# HDSC_HC32F480 register map
Vendor: HDSC Co.Ltd; Series: ARMCM4; File version: 1.2
CPU: CM0 r0p0, little endian, no MPU, no FPU, 3 interrupt priority bits
Registers are 16-bit, read-write, reset 0x0 unless marked. A register's access mark holds for its fields unless they carry their own. Offsets are from the block's base; [hi:lo] are bit positions; {n}, {i} and the like mark numbered series; 'fields as' and 'values as' point back to an identical list.

## USF
Base 0x400C0000
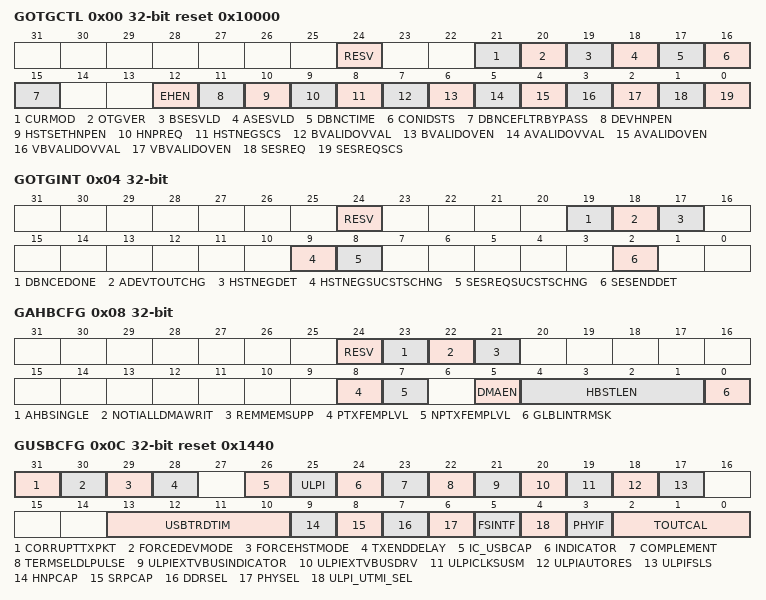
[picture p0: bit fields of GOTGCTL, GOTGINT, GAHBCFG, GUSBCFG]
0x00 GOTGCTL 32-bit ro reset 0x10000
  [24] RESV rw, [21] CURMOD, [20] OTGVER rw, [19] BSESVLD, [18] ASESVLD, [17] DBNCTIME, [16] CONIDSTS, [15] DBNCEFLTRBYPASS rw, [12] EHEN rw, [11] DEVHNPEN rw, [10] HSTSETHNPEN rw, [9] HNPREQ rw, [8] HSTNEGSCS, [7] BVALIDOVVAL rw, [6] BVALIDOVEN rw, [5] AVALIDOVVAL rw, [4] AVALIDOVEN rw, [3] VBVALIDOVVAL rw, [2] VBVALIDOVEN rw, [1] SESREQ rw, [0] SESREQSCS
0x04 GOTGINT 32-bit
  [24] RESV, [19] DBNCEDONE, [18] ADEVTOUTCHG, [17] HSTNEGDET, [9] HSTNEGSUCSTSCHNG, [8] SESREQSUCSTSCHNG, [2] SESENDDET
0x08 GAHBCFG 32-bit
  [24] RESV, [23] AHBSINGLE, [22] NOTIALLDMAWRIT, [21] REMMEMSUPP, [8] PTXFEMPLVL, [7] NPTXFEMPLVL, [5] DMAEN, [4:1] HBSTLEN, [0] GLBLINTRMSK
0x0C GUSBCFG 32-bit reset 0x1440
  [31] CORRUPTTXPKT wo, [30] FORCEDEVMODE, [29] FORCEHSTMODE, [28] TXENDDELAY, [26] IC_USBCAP, [25] ULPI, [24] INDICATOR, [23] COMPLEMENT, [22] TERMSELDLPULSE, [21] ULPIEXTVBUSINDICATOR, [20] ULPIEXTVBUSDRV, [19] ULPICLKSUSM, [18] ULPIAUTORES, [17] ULPIFSLS, [13:10] USBTRDTIM, [9] HNPCAP, [8] SRPCAP, [7] DDRSEL, [6] PHYSEL, [5] FSINTF, [4] ULPI_UTMI_SEL, [3] PHYIF, [2:0] TOUTCAL
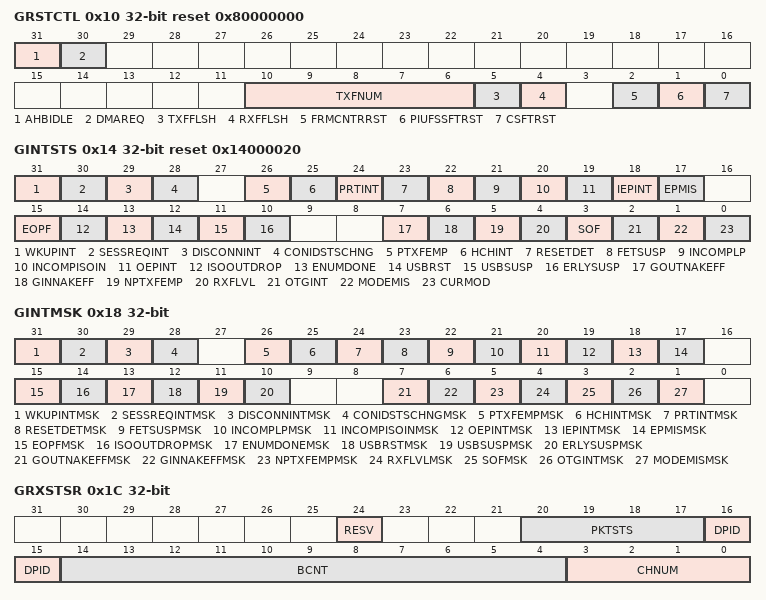
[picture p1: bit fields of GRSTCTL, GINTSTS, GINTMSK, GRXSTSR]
0x10 GRSTCTL 32-bit reset 0x80000000
  [31] AHBIDLE ro, [30] DMAREQ ro, [10:6] TXFNUM, [5] TXFFLSH, [4] RXFFLSH, [2] FRMCNTRRST, [1] PIUFSSFTRST, [0] CSFTRST
0x14 GINTSTS 32-bit ro reset 0x14000020
  [31] WKUPINT rw, [30] SESSREQINT rw, [29] DISCONNINT rw, [28] CONIDSTSCHNG rw, [26] PTXFEMP, [25] HCHINT, [24] PRTINT, [23] RESETDET rw, [22] FETSUSP rw, [21] INCOMPLP rw, [20] INCOMPISOIN rw, [19] OEPINT, [18] IEPINT, [17] EPMIS rw, [15] EOPF rw, [14] ISOOUTDROP rw, [13] ENUMDONE rw, [12] USBRST rw, [11] USBSUSP rw, [10] ERLYSUSP rw, [7] GOUTNAKEFF, [6] GINNAKEFF, [5] NPTXFEMP, [4] RXFLVL, [3] SOF rw, [2] OTGINT, [1] MODEMIS rw, [0] CURMOD
0x18 GINTMSK 32-bit
  [31] WKUPINTMSK, [30] SESSREQINTMSK, [29] DISCONNINTMSK, [28] CONIDSTSCHNGMSK, [26] PTXFEMPMSK, [25] HCHINTMSK, [24] PRTINTMSK, [23] RESETDETMSK, [22] FETSUSPMSK, [21] INCOMPLPMSK, [20] INCOMPISOINMSK, [19] OEPINTMSK, [18] IEPINTMSK, [17] EPMISMSK, [15] EOPFMSK, [14] ISOOUTDROPMSK, [13] ENUMDONEMSK, [12] USBRSTMSK, [11] USBSUSPMSK, [10] ERLYSUSPMSK, [7] GOUTNAKEFFMSK, [6] GINNAKEFFMSK, [5] NPTXFEMPMSK, [4] RXFLVLMSK, [3] SOFMSK, [2] OTGINTMSK, [1] MODEMISMSK
0x1C GRXSTSR 32-bit ro
  [24] RESV rw, [20:17] PKTSTS, [16:15] DPID, [14:4] BCNT, [3:0] CHNUM
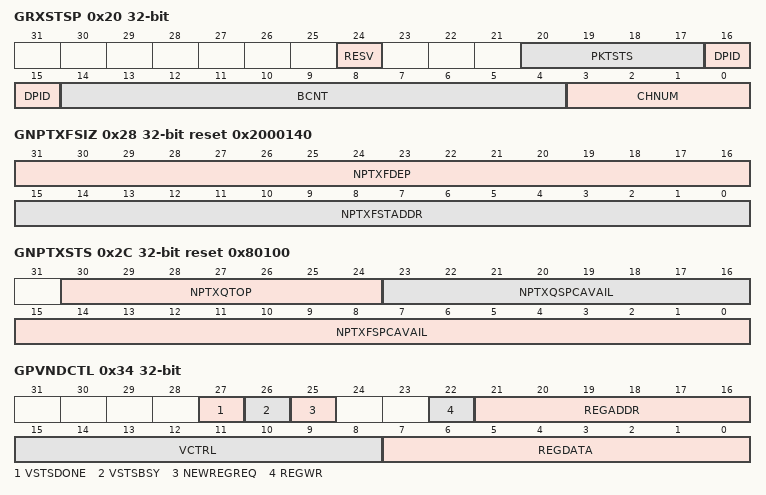
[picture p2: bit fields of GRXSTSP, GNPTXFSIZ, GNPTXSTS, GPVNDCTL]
0x20 GRXSTSP 32-bit ro
  [24] RESV rw, [20:17] PKTSTS, [16:15] DPID, [14:4] BCNT, [3:0] CHNUM
0x24 GRXFSIZ reset 0x140
  [10:0] RXFDEP
0x28 GNPTXFSIZ 32-bit reset 0x2000140
  [31:16] NPTXFDEP, [15:0] NPTXFSTADDR
0x2C GNPTXSTS 32-bit ro reset 0x80100
  [30:24] NPTXQTOP, [23:16] NPTXQSPCAVAIL, [15:0] NPTXFSPCAVAIL
0x34 GPVNDCTL 32-bit
  [27] VSTSDONE, [26] VSTSBSY ro, [25] NEWREGREQ, [22] REGWR, [21:16] REGADDR, [15:8] VCTRL, [7:0] REGDATA
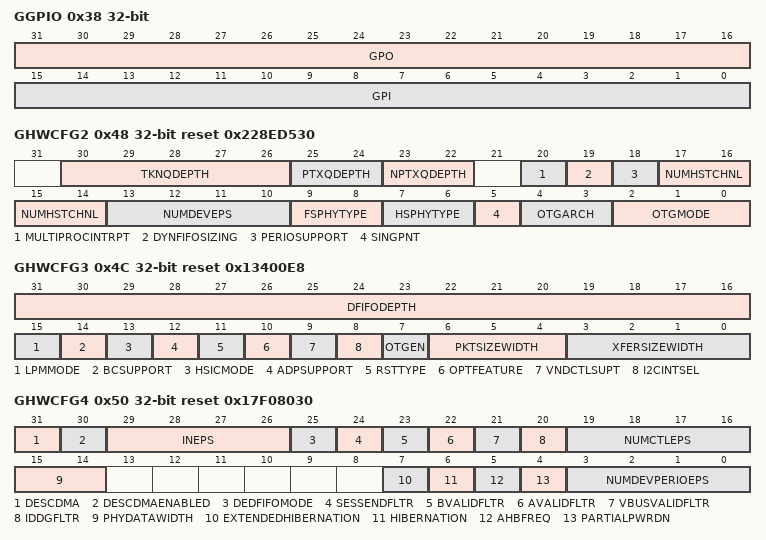
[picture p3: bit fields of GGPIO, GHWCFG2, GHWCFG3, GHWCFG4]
0x38 GGPIO 32-bit ro
  [31:16] GPO rw, [15:0] GPI
0x3C GUID 32-bit ro reset 0x12345678
0x40 GSNPSID 32-bit ro reset 0x4F54330A
0x44 GHWCFG1 32-bit ro
0x48 GHWCFG2 32-bit ro reset 0x228ED530
  [30:26] TKNQDEPTH, [25:24] PTXQDEPTH, [23:22] NPTXQDEPTH, [20] MULTIPROCINTRPT, [19] DYNFIFOSIZING, [18] PERIOSUPPORT, [17:14] NUMHSTCHNL, [13:10] NUMDEVEPS, [9:8] FSPHYTYPE, [7:6] HSPHYTYPE, [5] SINGPNT, [4:3] OTGARCH, [2:0] OTGMODE
0x4C GHWCFG3 32-bit ro reset 0x13400E8
  [31:16] DFIFODEPTH, [15] LPMMODE, [14] BCSUPPORT, [13] HSICMODE, [12] ADPSUPPORT, [11] RSTTYPE, [10] OPTFEATURE, [9] VNDCTLSUPT, [8] I2CINTSEL, [7] OTGEN, [6:4] PKTSIZEWIDTH, [3:0] XFERSIZEWIDTH
0x50 GHWCFG4 32-bit ro reset 0x17F08030
  [31] DESCDMA, [30] DESCDMAENABLED, [29:26] INEPS, [25] DEDFIFOMODE, [24] SESSENDFLTR, [23] BVALIDFLTR, [22] AVALIDFLTR, [21] VBUSVALIDFLTR, [20] IDDGFLTR, [19:16] NUMCTLEPS, [15:14] PHYDATAWIDTH, [7] EXTENDEDHIBERNATION, [6] HIBERNATION, [5] AHBFREQ, [4] PARTIALPWRDN, [3:0] NUMDEVPERIOEPS
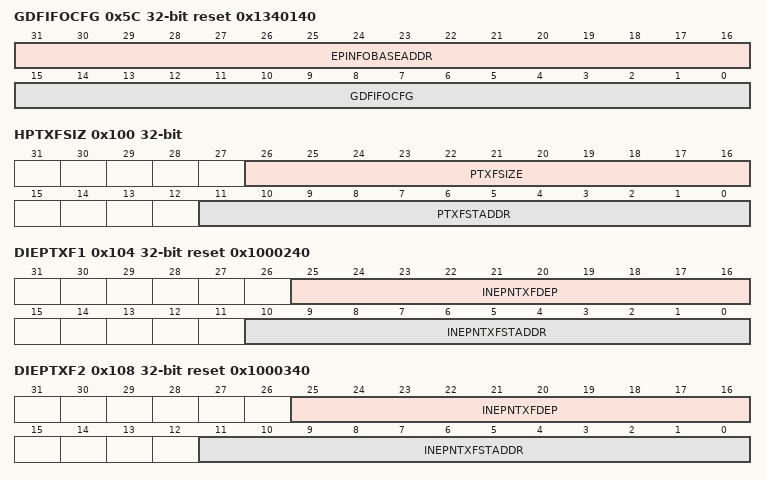
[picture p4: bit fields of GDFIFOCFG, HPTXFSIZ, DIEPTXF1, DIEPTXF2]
0x5C GDFIFOCFG 32-bit reset 0x1340140
  [31:16] EPINFOBASEADDR, [15:0] GDFIFOCFG
0x100 HPTXFSIZ 32-bit
  [26:16] PTXFSIZE, [11:0] PTXFSTADDR
0x104 DIEPTXF1 32-bit reset 0x1000240
  [25:16] INEPNTXFDEP, [10:0] INEPNTXFSTADDR
0x108 DIEPTXF2 32-bit reset 0x1000340
  [25:16] INEPNTXFDEP, [11:0] INEPNTXFSTADDR
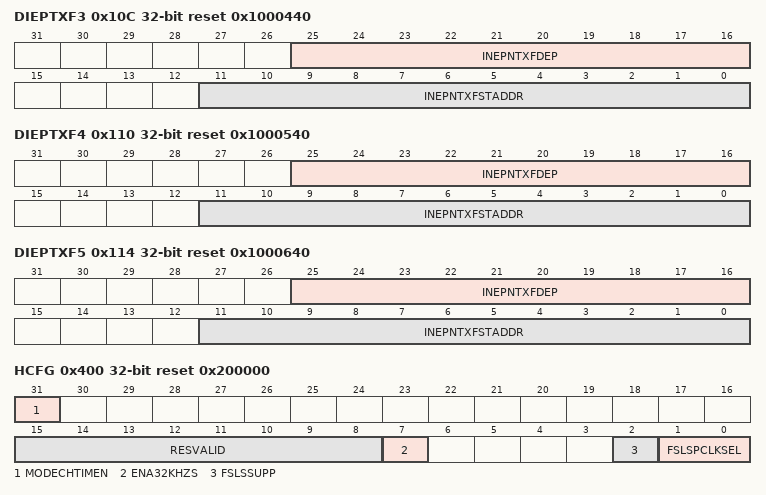
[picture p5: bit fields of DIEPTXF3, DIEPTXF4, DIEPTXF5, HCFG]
0x10C DIEPTXF3 32-bit reset 0x1000440
  [25:16] INEPNTXFDEP, [11:0] INEPNTXFSTADDR
0x110 DIEPTXF4 32-bit reset 0x1000540
  [25:16] INEPNTXFDEP, [11:0] INEPNTXFSTADDR
0x114 DIEPTXF5 32-bit reset 0x1000640
  [25:16] INEPNTXFDEP, [11:0] INEPNTXFSTADDR
0x400 HCFG 32-bit reset 0x200000
  [31] MODECHTIMEN, [15:8] RESVALID, [7] ENA32KHZS, [2] FSLSSUPP, [1:0] FSLSPCLKSEL
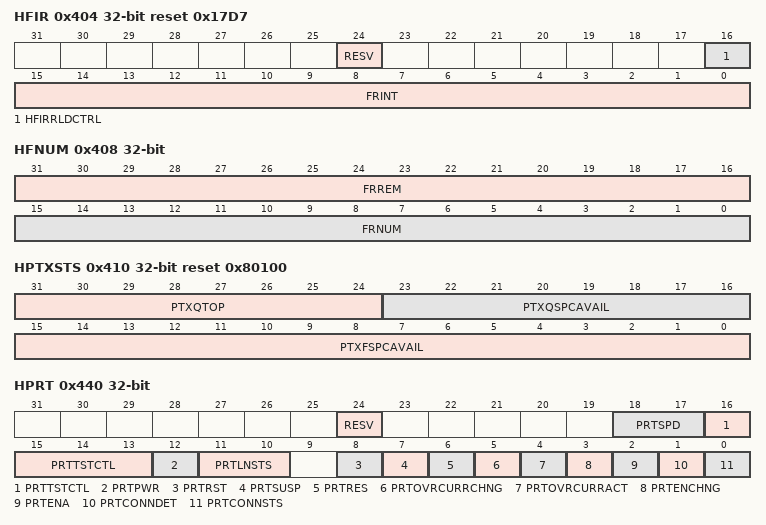
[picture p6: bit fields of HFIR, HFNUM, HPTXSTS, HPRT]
0x404 HFIR 32-bit reset 0x17D7
  [24] RESV, [16] HFIRRLDCTRL, [15:0] FRINT
0x408 HFNUM 32-bit ro
  [31:16] FRREM, [15:0] FRNUM
0x410 HPTXSTS 32-bit ro reset 0x80100
  [31:24] PTXQTOP, [23:16] PTXQSPCAVAIL, [15:0] PTXFSPCAVAIL
0x414 HAINT ro
0x418 HAINTMSK
0x440 HPRT 32-bit ro
  [24] RESV rw, [18:17] PRTSPD, [16:13] PRTTSTCTL rw, [12] PRTPWR rw, [11:10] PRTLNSTS, [8] PRTRST rw, [7] PRTSUSP rw, [6] PRTRES rw, [5] PRTOVRCURRCHNG rw, [4] PRTOVRCURRACT, [3] PRTENCHNG rw, [2] PRTENA rw, [1] PRTCONNDET rw, [0] PRTCONNSTS
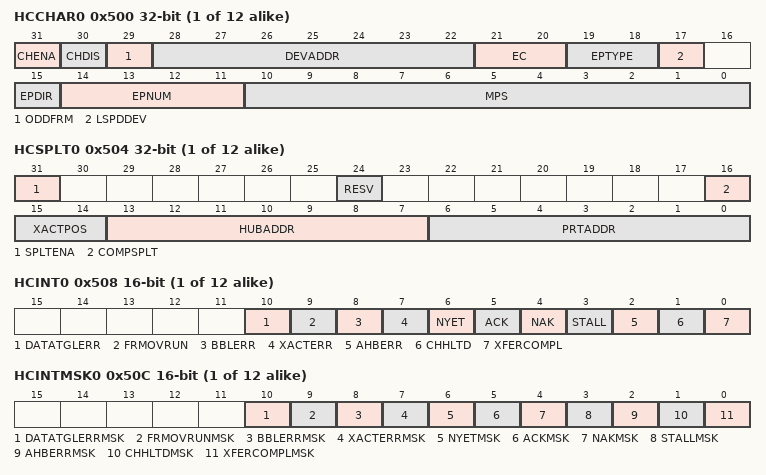
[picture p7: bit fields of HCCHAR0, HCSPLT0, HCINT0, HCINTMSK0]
{0x500+0x20*i} HCCHAR{i} 32-bit (i=0..11)
  [31] CHENA, [30] CHDIS, [29] ODDFRM, [28:22] DEVADDR, [21:20] EC, [19:18] EPTYPE ro, [17] LSPDDEV, [15] EPDIR, [14:11] EPNUM, [10:0] MPS
{0x504+0x20*i} HCSPLT{i} 32-bit (i=0..11)
  [31] SPLTENA, [24] RESV, [16] COMPSPLT, [15:14] XACTPOS, [13:7] HUBADDR, [6:0] PRTADDR
{0x508+0x20*i} HCINT{i} (i=0..11)
  [10] DATATGLERR, [9] FRMOVRUN, [8] BBLERR, [7] XACTERR, [6] NYET, [5] ACK, [4] NAK, [3] STALL, [2] AHBERR, [1] CHHLTD, [0] XFERCOMPL
{0x50C+0x20*i} HCINTMSK{i} (i=0..11)
  [10] DATATGLERRMSK, [9] FRMOVRUNMSK, [8] BBLERRMSK, [7] XACTERRMSK, [6] NYETMSK, [5] ACKMSK, [4] NAKMSK, [3] STALLMSK, [2] AHBERRMSK, [1] CHHLTDMSK, [0] XFERCOMPLMSK
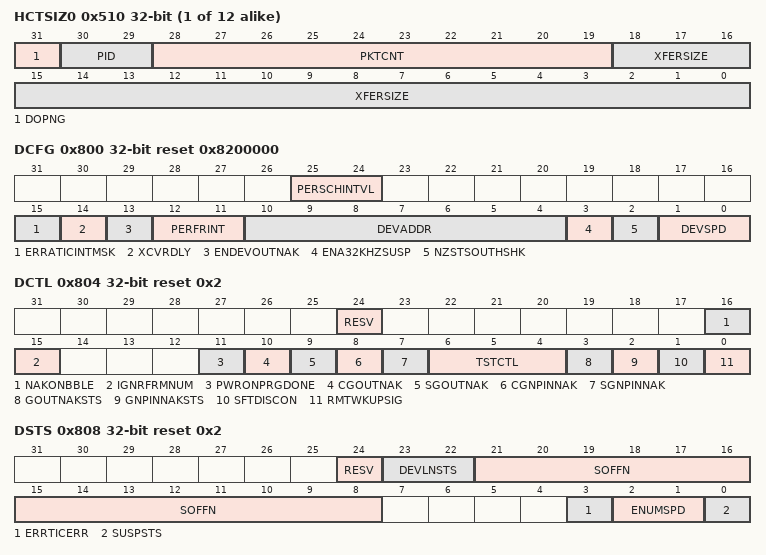
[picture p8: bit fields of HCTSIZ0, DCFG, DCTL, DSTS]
{0x510+0x20*i} HCTSIZ{i} 32-bit (i=0..11)
  [31] DOPNG, [30:29] PID, [28:19] PKTCNT, [18:0] XFERSIZE
{0x514+0x20*i} HCDMA{i} 32-bit (i=0..11)
0x800 DCFG 32-bit reset 0x8200000
  [25:24] PERSCHINTVL, [15] ERRATICINTMSK, [14] XCVRDLY, [13] ENDEVOUTNAK, [12:11] PERFRINT, [10:4] DEVADDR, [3] ENA32KHZSUSP, [2] NZSTSOUTHSHK, [1:0] DEVSPD
0x804 DCTL 32-bit reset 0x2
  [24] RESV, [16] NAKONBBLE, [15] IGNRFRMNUM, [11] PWRONPRGDONE, [10] CGOUTNAK wo, [9] SGOUTNAK wo, [8] CGNPINNAK wo, [7] SGNPINNAK wo, [6:4] TSTCTL, [3] GOUTNAKSTS ro, [2] GNPINNAKSTS ro, [1] SFTDISCON, [0] RMTWKUPSIG
0x808 DSTS 32-bit ro reset 0x2
  [24] RESV rw, [23:22] DEVLNSTS, [21:8] SOFFN, [3] ERRTICERR, [2:1] ENUMSPD, [0] SUSPSTS
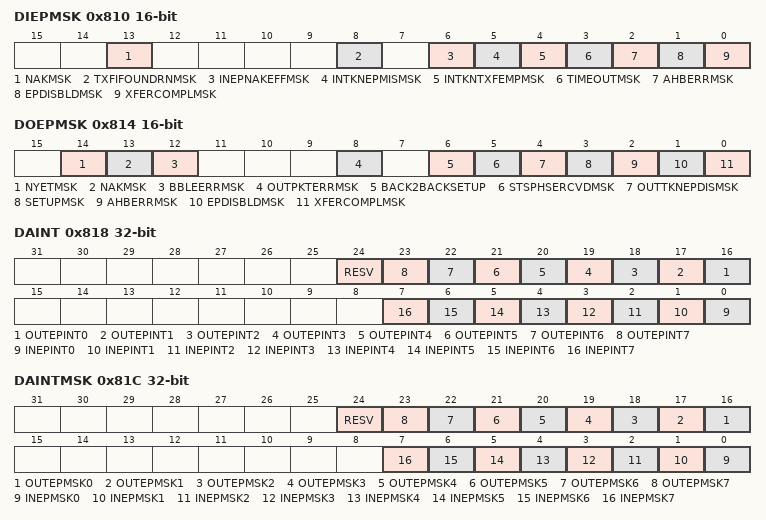
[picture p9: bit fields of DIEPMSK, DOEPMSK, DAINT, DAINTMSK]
0x810 DIEPMSK
  [13] NAKMSK, [8] TXFIFOUNDRNMSK, [6] INEPNAKEFFMSK, [5] INTKNEPMISMSK, [4] INTKNTXFEMPMSK, [3] TIMEOUTMSK, [2] AHBERRMSK, [1] EPDISBLDMSK, [0] XFERCOMPLMSK
0x814 DOEPMSK
  [14] NYETMSK, [13] NAKMSK, [12] BBLEERRMSK, [8] OUTPKTERRMSK, [6] BACK2BACKSETUP, [5] STSPHSERCVDMSK, [4] OUTTKNEPDISMSK, [3] SETUPMSK, [2] AHBERRMSK, [1] EPDISBLDMSK, [0] XFERCOMPLMSK
0x818 DAINT 32-bit ro
  [24] RESV rw, [n+16] OUTEPINT{n} (n=0..7), [n] INEPINT{n} (n=0..7)
0x81C DAINTMSK 32-bit
  [24] RESV, [n+16] OUTEPMSK{n} (n=0..7), [n] INEPMSK{n} (n=0..7)
0x828 DVBUSDIS reset 0x17D7
0x82C DVBUSPULSE reset 0x5B8
  [11:0] DVBUSPULSE
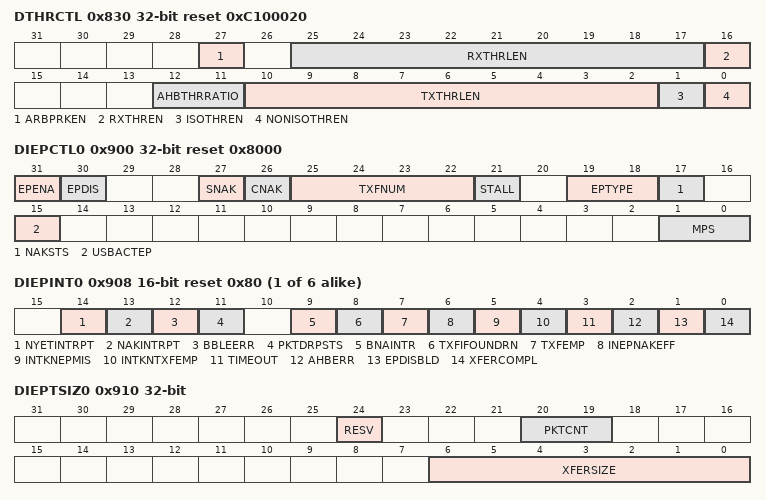
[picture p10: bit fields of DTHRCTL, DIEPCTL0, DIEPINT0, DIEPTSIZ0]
0x830 DTHRCTL 32-bit reset 0xC100020
  [27] ARBPRKEN, [25:17] RXTHRLEN, [16] RXTHREN, [12:11] AHBTHRRATIO, [10:2] TXTHRLEN, [1] ISOTHREN, [0] NONISOTHREN
0x834 DIEPEMPMSK
0x900 DIEPCTL0 32-bit ro reset 0x8000
  [31] EPENA rw, [30] EPDIS, [27] SNAK wo, [26] CNAK wo, [25:22] TXFNUM rw, [21] STALL rw, [19:18] EPTYPE, [17] NAKSTS, [15] USBACTEP, [1:0] MPS
{0x908+0x20*i} DIEPINT{i} reset 0x80 (i=0..5)
  [14] NYETINTRPT, [13] NAKINTRPT, [12] BBLEERR, [11] PKTDRPSTS, [9] BNAINTR, [8] TXFIFOUNDRN, [7] TXFEMP ro, [6] INEPNAKEFF, [5] INTKNEPMIS, [4] INTKNTXFEMP, [3] TIMEOUT, [2] AHBERR, [1] EPDISBLD, [0] XFERCOMPL
0x910 DIEPTSIZ0 32-bit
  [24] RESV, [20:19] PKTCNT, [6:0] XFERSIZE
{0x914+0x20*i} DIEPDMA{i} 32-bit (i=0..5)
{0x918+0x20*i} DTXFSTS{i} ro reset 0x100 (i=0..5)
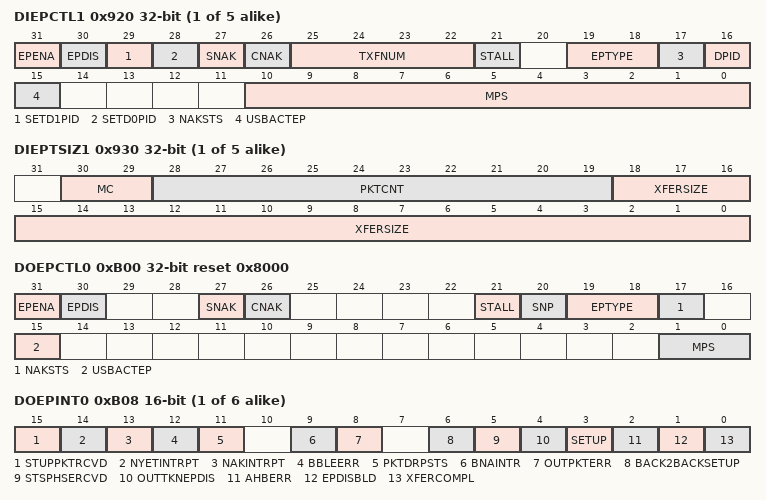
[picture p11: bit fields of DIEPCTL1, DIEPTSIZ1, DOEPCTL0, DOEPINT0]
{0x900+0x20*i} DIEPCTL{i} 32-bit (i=1..5)
  [31] EPENA, [30] EPDIS ro, [29] SETD1PID wo, [28] SETD0PID wo, [27] SNAK wo, [26] CNAK wo, [25:22] TXFNUM, [21] STALL, [19:18] EPTYPE ro, [17] NAKSTS ro, [16] DPID ro, [15] USBACTEP ro, [10:0] MPS
{0x910+0x20*i} DIEPTSIZ{i} 32-bit (i=1..5)
  [30:29] MC, [28:19] PKTCNT, [18:0] XFERSIZE
0xB00 DOEPCTL0 32-bit ro reset 0x8000
  [31] EPENA rw, [30] EPDIS, [27] SNAK wo, [26] CNAK wo, [21] STALL rw, [20] SNP rw, [19:18] EPTYPE, [17] NAKSTS, [15] USBACTEP, [1:0] MPS
{0xB08+0x20*i} DOEPINT{i} (i=0..5)
  [15] STUPPKTRCVD, [14] NYETINTRPT, [13] NAKINTRPT, [12] BBLEERR, [11] PKTDRPSTS, [9] BNAINTR, [8] OUTPKTERR, [6] BACK2BACKSETUP, [5] STSPHSERCVD, [4] OUTTKNEPDIS, [3] SETUP, [2] AHBERR, [1] EPDISBLD, [0] XFERCOMPL
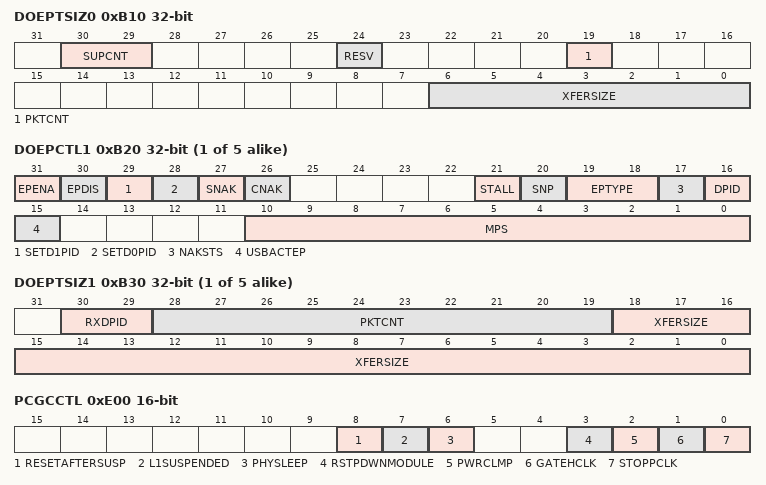
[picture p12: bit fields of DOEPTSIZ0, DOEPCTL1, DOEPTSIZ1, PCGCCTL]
0xB10 DOEPTSIZ0 32-bit
  [30:29] SUPCNT, [24] RESV, [19] PKTCNT, [6:0] XFERSIZE
{0xB14+0x20*i} DOEPDMA{i} 32-bit (i=0..5)
{0xB00+0x20*i} DOEPCTL{i} 32-bit (i=1..5)
  [31] EPENA, [30] EPDIS ro, [29] SETD1PID wo, [28] SETD0PID wo, [27] SNAK wo, [26] CNAK wo, [21] STALL, [20] SNP, [19:18] EPTYPE ro, [17] NAKSTS ro, [16] DPID ro, [15] USBACTEP ro, [10:0] MPS
{0xB10+0x20*i} DOEPTSIZ{i} 32-bit (i=1..5)
  [30:29] RXDPID ro, [28:19] PKTCNT, [18:0] XFERSIZE
0xE00 PCGCCTL
  [8] RESETAFTERSUSP ro, [7] L1SUSPENDED ro, [6] PHYSLEEP ro, [3] RSTPDWNMODULE, [2] PWRCLMP, [1] GATEHCLK, [0] STOPPCLK

## USH
Base 0x40080000
Registers as USF; these are added or differ:
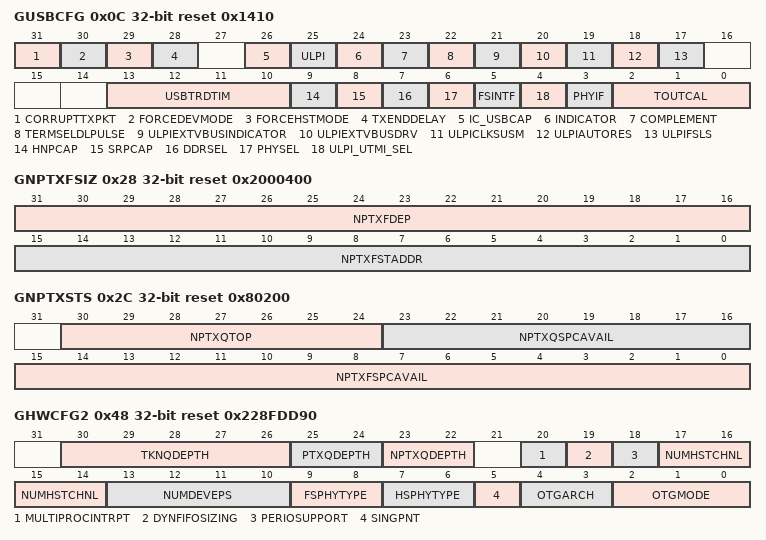
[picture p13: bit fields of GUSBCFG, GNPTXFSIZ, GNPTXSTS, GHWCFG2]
0x0C GUSBCFG 32-bit reset 0x1410
  fields as USF.GUSBCFG
0x24 GRXFSIZ reset 0x400
  [10:0] RXFDEP
0x28 GNPTXFSIZ 32-bit reset 0x2000400
  [31:16] NPTXFDEP, [15:0] NPTXFSTADDR
0x2C GNPTXSTS 32-bit ro reset 0x80200
  [30:24] NPTXQTOP, [23:16] NPTXQSPCAVAIL, [15:0] NPTXFSPCAVAIL
0x48 GHWCFG2 32-bit ro reset 0x228FDD90
  fields as USF.GHWCFG2
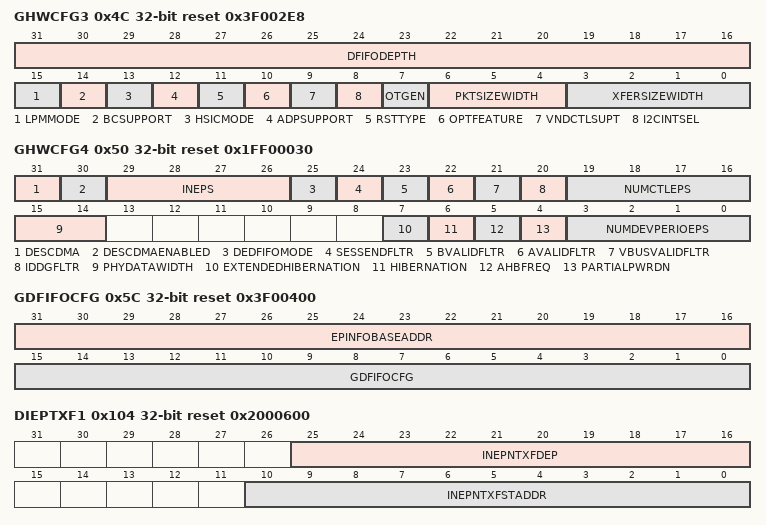
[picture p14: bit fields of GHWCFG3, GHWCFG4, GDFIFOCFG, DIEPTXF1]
0x4C GHWCFG3 32-bit ro reset 0x3F002E8
  [31:16] DFIFODEPTH, [15] LPMMODE, [14] BCSUPPORT, [13] HSICMODE, [12] ADPSUPPORT, [11] RSTTYPE, [10] OPTFEATURE, [9] VNDCTLSUPT, [8] I2CINTSEL, [7] OTGEN, [6:4] PKTSIZEWIDTH, [3:0] XFERSIZEWIDTH
0x50 GHWCFG4 32-bit ro reset 0x1FF00030
  fields as USF.GHWCFG4
0x5C GDFIFOCFG 32-bit reset 0x3F00400
  [31:16] EPINFOBASEADDR, [15:0] GDFIFOCFG
0x104 DIEPTXF1 32-bit reset 0x2000600
  [25:16] INEPNTXFDEP, [10:0] INEPNTXFSTADDR
0x108 DIEPTXF2 32-bit reset 0x2000800
  [25:16] INEPNTXFDEP, [11:0] INEPNTXFSTADDR
0x10C DIEPTXF3 32-bit reset 0x2000A00
  [25:16] INEPNTXFDEP, [11:0] INEPNTXFSTADDR
0x110 DIEPTXF4 32-bit reset 0x2000C00
  [25:16] INEPNTXFDEP, [11:0] INEPNTXFSTADDR
0x114 DIEPTXF5 32-bit reset 0x2000E00
  [25:16] INEPNTXFDEP, [11:0] INEPNTXFSTADDR
0x118 DIEPTXF6 32-bit reset 0x2001000
  [25:16] INEPNTXFDEP, [12:0] INEPNTXFSTADDR
0x11C DIEPTXF7 32-bit reset 0x2001200
  [25:16] INEPNTXFDEP, [12:0] INEPNTXFSTADDR
0x410 HPTXSTS 32-bit ro reset 0x80200
  [31:24] PTXQTOP, [23:16] PTXQSPCAVAIL, [15:0] PTXFSPCAVAIL
{0x504+0x20*i} HCSPLT{i} 32-bit (i=0..15)
  [31] SPLTENA, [16] COMPSPLT, [15:14] XACTPOS, [13:7] HUBADDR, [6:0] PRTADDR
0x514 HCDMA0 32-bit reset 0x20002000
{0x500+0x20*i} HCCHAR{i} 32-bit (i=12..15)
  [31] CHENA, [30] CHDIS, [29] ODDFRM, [28:22] DEVADDR, [21:20] EC, [19:18] EPTYPE ro, [17] LSPDDEV, [15] EPDIR, [14:11] EPNUM, [10:0] MPS
{0x508+0x20*i} HCINT{i} (i=12..15)
  [10] DATATGLERR, [9] FRMOVRUN, [8] BBLERR, [7] XACTERR, [6] NYET, [5] ACK, [4] NAK, [3] STALL, [2] AHBERR, [1] CHHLTD, [0] XFERCOMPL
{0x50C+0x20*i} HCINTMSK{i} (i=12..15)
  [10] DATATGLERRMSK, [9] FRMOVRUNMSK, [8] BBLERRMSK, [7] XACTERRMSK, [6] NYETMSK, [5] ACKMSK, [4] NAKMSK, [3] STALLMSK, [2] AHBERRMSK, [1] CHHLTDMSK, [0] XFERCOMPLMSK
{0x510+0x20*i} HCTSIZ{i} 32-bit (i=12..15)
  [31] DOPNG, [30:29] PID, [28:19] PKTCNT, [18:0] XFERSIZE
{0x514+0x20*i} HCDMA{i} 32-bit (i=12..15)
{0x918+0x20*i} DTXFSTS{i} ro reset 0x200 (i=0..7)
0x9C0 DIEPCTL6 32-bit
  [31] EPENA, [30] EPDIS ro, [29] SETD1PID wo, [28] SETD0PID wo, [27] SNAK wo, [26] CNAK wo, [25:22] TXFNUM, [21] STALL, [19:18] EPTYPE ro, [17] NAKSTS ro, [16] DPID ro, [15] USBACTEP ro, [10:0] MPS
0x9C8 DIEPINT6 reset 0x80
  fields as USF.DIEPINT0
0x9D0 DIEPTSIZ6 32-bit
  [30:29] MC, [28:19] PKTCNT, [18:0] XFERSIZE
0x9D4 DIEPDMA6 32-bit
0x9E0 DIEPCTL7 32-bit
  fields as DIEPCTL6
0x9E8 DIEPINT7 reset 0x80
  fields as USF.DIEPINT0
0x9F0 DIEPTSIZ7 32-bit
  [30:29] MC, [28:19] PKTCNT, [18:0] XFERSIZE
0x9F4 DIEPDMA7 32-bit
0xB10 DOEPTSIZ0 32-bit
  [30:29] SUPCNT, [19] PKTCNT, [6:0] XFERSIZE
0xB14 DOEPDMA0 32-bit reset 0x20002000
0xBC0 DOEPCTL6 32-bit
  [31] EPENA, [30] EPDIS ro, [29] SETD1PID wo, [28] SETD0PID wo, [27] SNAK wo, [26] CNAK wo, [21] STALL, [20] SNP, [19:18] EPTYPE ro, [17] NAKSTS ro, [16] DPID ro, [15] USBACTEP ro, [10:0] MPS
0xBC8 DOEPINT6
  fields as USF.DOEPINT0
0xBD0 DOEPTSIZ6 32-bit
  [30:29] RXDPID ro, [28:19] PKTCNT, [18:0] XFERSIZE
0xBD4 DOEPDMA6 32-bit
0xBE0 DOEPCTL7 32-bit
  fields as DOEPCTL6
0xBE8 DOEPINT7
  fields as USF.DOEPINT0
0xBF0 DOEPTSIZ7 32-bit
  [30:29] RXDPID ro, [28:19] PKTCNT, [18:0] XFERSIZE
0xBF4 DOEPDMA7 32-bit
